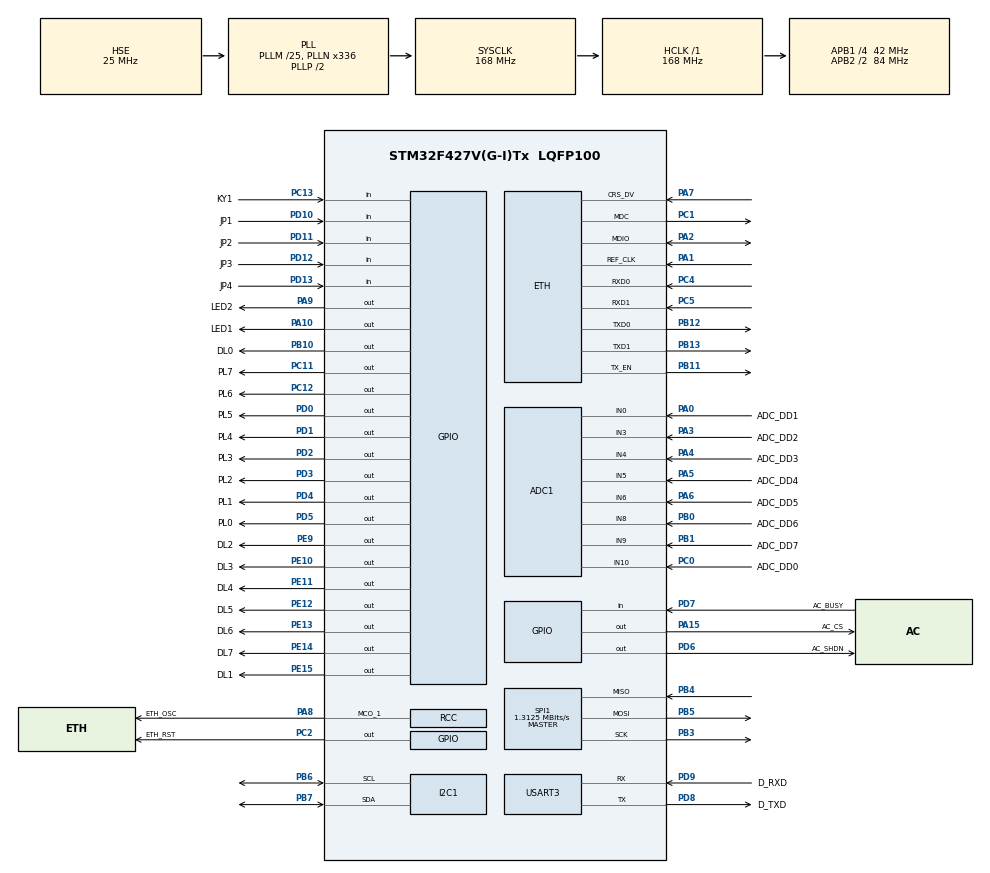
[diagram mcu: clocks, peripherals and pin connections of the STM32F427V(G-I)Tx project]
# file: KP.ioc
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ADC1.Channel-0\#ChannelRegularConversion=ADC_CHANNEL_10
ADC1.Channel-1\#ChannelRegularConversion=ADC_CHANNEL_0
ADC1.Channel-2\#ChannelRegularConversion=ADC_CHANNEL_3
ADC1.Channel-3\#ChannelRegularConversion=ADC_CHANNEL_4
ADC1.Channel-4\#ChannelRegularConversion=ADC_CHANNEL_5
ADC1.Channel-5\#ChannelRegularConversion=ADC_CHANNEL_6
ADC1.Channel-6\#ChannelRegularConversion=ADC_CHANNEL_8
ADC1.Channel-7\#ChannelRegularConversion=ADC_CHANNEL_9
ADC1.ContinuousConvMode=ENABLE
ADC1.DMAContinuousRequests=ENABLE
ADC1.ExternalTrigConv=ADC_SOFTWARE_START
ADC1.NbrOfConversion=8
ADC1.NbrOfConversionFlag=1
ADC1.Rank-0\#ChannelRegularConversion=1
ADC1.Rank-1\#ChannelRegularConversion=2
ADC1.Rank-2\#ChannelRegularConversion=3
ADC1.Rank-3\#ChannelRegularConversion=4
ADC1.Rank-4\#ChannelRegularConversion=5
ADC1.Rank-5\#ChannelRegularConversion=6
ADC1.Rank-6\#ChannelRegularConversion=7
ADC1.Rank-7\#ChannelRegularConversion=8
ADC1.SamplingTime-0\#ChannelRegularConversion=ADC_SAMPLETIME_15CYCLES
ADC1.SamplingTime-1\#ChannelRegularConversion=ADC_SAMPLETIME_15CYCLES
ADC1.SamplingTime-2\#ChannelRegularConversion=ADC_SAMPLETIME_15CYCLES
ADC1.SamplingTime-3\#ChannelRegularConversion=ADC_SAMPLETIME_15CYCLES
ADC1.SamplingTime-4\#ChannelRegularConversion=ADC_SAMPLETIME_15CYCLES
ADC1.SamplingTime-5\#ChannelRegularConversion=ADC_SAMPLETIME_15CYCLES
ADC1.SamplingTime-6\#ChannelRegularConversion=ADC_SAMPLETIME_15CYCLES
ADC1.SamplingTime-7\#ChannelRegularConversion=ADC_SAMPLETIME_15CYCLES
ADC1.ScanConvMode=ENABLE
ADC1.master=1
Dma.ADC1.0.Direction=DMA_PERIPH_TO_MEMORY
Dma.ADC1.0.FIFOMode=DMA_FIFOMODE_DISABLE
Dma.ADC1.0.Instance=DMA2_Stream0
Dma.ADC1.0.MemDataAlignment=DMA_MDATAALIGN_HALFWORD
Dma.ADC1.0.MemInc=DMA_MINC_ENABLE
Dma.ADC1.0.Mode=DMA_NORMAL
Dma.ADC1.0.PeriphDataAlignment=DMA_PDATAALIGN_HALFWORD
Dma.ADC1.0.PeriphInc=DMA_PINC_DISABLE
Dma.ADC1.0.Priority=DMA_PRIORITY_LOW
Dma.Request0=ADC1
Dma.Request1=SPI1_RX
Dma.Request2=SPI1_TX
Dma.SPI1_RX.1.Direction=DMA_PERIPH_TO_MEMORY
Dma.SPI1_RX.1.FIFOMode=DMA_FIFOMODE_DISABLE
Dma.SPI1_RX.1.Instance=DMA2_Stream2
Dma.SPI1_RX.1.MemDataAlignment=DMA_MDATAALIGN_BYTE
Dma.SPI1_RX.1.MemInc=DMA_MINC_ENABLE
Dma.SPI1_RX.1.Mode=DMA_NORMAL
Dma.SPI1_RX.1.PeriphDataAlignment=DMA_PDATAALIGN_BYTE
Dma.SPI1_RX.1.PeriphInc=DMA_PINC_DISABLE
Dma.SPI1_RX.1.Priority=DMA_PRIORITY_LOW
Dma.SPI1_TX.2.Direction=DMA_MEMORY_TO_PERIPH
Dma.SPI1_TX.2.FIFOMode=DMA_FIFOMODE_DISABLE
Dma.SPI1_TX.2.Instance=DMA2_Stream3
Dma.SPI1_TX.2.MemDataAlignment=DMA_MDATAALIGN_BYTE
Dma.SPI1_TX.2.MemInc=DMA_MINC_ENABLE
Dma.SPI1_TX.2.Mode=DMA_NORMAL
Dma.SPI1_TX.2.PeriphDataAlignment=DMA_PDATAALIGN_BYTE
Dma.SPI1_TX.2.PeriphInc=DMA_PINC_DISABLE
Dma.SPI1_TX.2.Priority=DMA_PRIORITY_LOW
ETH.MACAddr=00\:80\:E1\:00\:12\:35
ETH.MediaInterface=ETH_MEDIA_INTERFACE_RMII
ETH.PhyAddress=0
FREERTOS.Mutexes01=mutex_OutText,Static,mutex_OutTextControlBlock
FREERTOS.Tasks01=defaultTask,0,512,StartDefaultTask,Default,NULL,Dynamic,NULL,NULL
FREERTOS.configGENERATE_RUN_TIME_STATS=0
FREERTOS.configMINIMAL_STACK_SIZE=128
FREERTOS.configTOTAL_HEAP_SIZE=49152
FREERTOS.configUSE_NEWLIB_REENTRANT=1
FREERTOS.configUSE_STATS_FORMATTING_FUNCTIONS=1
FREERTOS.configUSE_TIMERS=1
FREERTOS.configUSE_TRACE_FACILITY=1
LWIP.DEFAULT_RAW_RECVMBOX_SIZE=6
LWIP.GATEWAY_ADDRESS=192.168.254.254
LWIP.IP_ADDRESS=192.168.254.191
LWIP.LWIP_DHCP=1
LWIP.LWIP_DNS=1
LWIP.LWIP_NETIF_STATUS_CALLBACK=1
LWIP.LWIP_RAW=1
LWIP.LWIP_SO_RCVTIMEO=1
LWIP.MEMP_NUM_TCP_PCB=5
LWIP.MEM_SIZE=24576
LWIP.NETMASK_ADDRESS=255.255.255.000
LWIP.Version=v2.1.2_Cube
Mcu.Family=STM32F4
Mcu.Name=STM32F427V(G-I)Tx
Mcu.Package=LQFP100
NVIC.DMA2_Stream0_IRQn=true\:8\:0\:true\:false\:true\:true\:false\:true
NVIC.DMA2_Stream2_IRQn=true\:6\:0\:true\:false\:true\:true\:false\:true
NVIC.DMA2_Stream3_IRQn=true\:6\:0\:true\:false\:true\:true\:false\:true
NVIC.ETH_IRQn=true\:7\:0\:true\:false\:true\:false\:false\:true
NVIC.PriorityGroup=NVIC_PRIORITYGROUP_4
NVIC.TIM1_UP_TIM10_IRQn=true\:0\:0\:false\:false\:true\:false\:false\:true
NVIC.TIM2_IRQn=true\:0\:0\:false\:false\:true\:true\:true\:true
NVIC.TimeBase=TIM1_UP_TIM10_IRQn
NVIC.TimeBaseIP=TIM1
PA0/WKUP.GPIO_Label=ADC_DD1
PA0/WKUP.Signal=ADCx_IN0
PA1.Mode=RMII
PA1.Signal=ETH_REF_CLK
PA10.GPIO_Label=LED1
PA10.PinState=GPIO_PIN_SET
PA10.Signal=GPIO_Output
PA13.Mode=Serial_Wire
PA13.Signal=SYS_JTMS-SWDIO
PA14.Mode=Serial_Wire
PA14.Signal=SYS_JTCK-SWCLK
PA15.GPIO_Label=AC_CS
PA15.GPIO_Speed=GPIO_SPEED_FREQ_HIGH
PA15.PinState=GPIO_PIN_SET
PA15.Signal=GPIO_Output
PA2.GPIO_PuPd=GPIO_PULLUP
PA2.Mode=RMII
PA2.Signal=ETH_MDIO
PA3.GPIO_Label=ADC_DD2
PA3.Signal=ADCx_IN3
PA4.GPIO_Label=ADC_DD3
PA4.Signal=ADCx_IN4
PA5.GPIO_Label=ADC_DD4
PA5.Signal=ADCx_IN5
PA6.GPIO_Label=ADC_DD5
PA6.Signal=ADCx_IN6
PA7.Mode=RMII
PA7.Signal=ETH_CRS_DV
PA8.GPIO_Label=ETH_OSC
PA8.Mode=Clock-out-1
PA8.Signal=RCC_MCO_1
PA9.GPIO_Label=LED2
PA9.PinState=GPIO_PIN_SET
PA9.Signal=GPIO_Output
PB0.GPIO_Label=ADC_DD6
PB0.Signal=ADCx_IN8
PB1.GPIO_Label=ADC_DD7
PB1.Signal=ADCx_IN9
PB10.GPIO_Label=DL0
PB10.Signal=GPIO_Output
PB11.Mode=RMII
PB11.Signal=ETH_TX_EN
PB12.Mode=RMII
PB12.Signal=ETH_TXD0
PB13.Mode=RMII
PB13.Signal=ETH_TXD1
PB3.Mode=Full_Duplex_Master
PB3.Signal=SPI1_SCK
PB4.Mode=Full_Duplex_Master
PB4.Signal=SPI1_MISO
PB5.Mode=Full_Duplex_Master
PB5.Signal=SPI1_MOSI
PB6.Mode=I2C
PB6.Signal=I2C1_SCL
PB7.Mode=I2C
PB7.Signal=I2C1_SDA
PC0.GPIO_Label=ADC_DD0
PC0.Signal=ADCx_IN10
PC1.Mode=RMII
PC1.Signal=ETH_MDC
PC11.GPIO_Label=PL7
PC11.Signal=GPIO_Output
PC12.GPIO_Label=PL6
PC12.Signal=GPIO_Output
PC13.GPIO_Label=KY1
PC13.Signal=GPIO_Input
PC2.GPIO_Label=ETH_RST
PC2.Signal=GPIO_Output
PC4.Mode=RMII
PC4.Signal=ETH_RXD0
PC5.Mode=RMII
PC5.Signal=ETH_RXD1
PD0.GPIO_Label=PL5
PD0.Signal=GPIO_Output
PD1.GPIO_Label=PL4
PD1.Signal=GPIO_Output
PD10.GPIO_Label=JP1
PD10.GPIO_PuPd=GPIO_PULLUP
PD10.Signal=GPIO_Input
PD11.GPIO_Label=JP2
PD11.GPIO_PuPd=GPIO_PULLUP
PD11.Signal=GPIO_Input
PD12.GPIO_Label=JP3
PD12.GPIO_PuPd=GPIO_PULLUP
PD12.Signal=GPIO_Input
PD13.GPIO_Label=JP4
PD13.GPIO_PuPd=GPIO_PULLUP
PD13.Signal=GPIO_Input
PD2.GPIO_Label=PL3
PD2.Signal=GPIO_Output
PD3.GPIO_Label=PL2
PD3.Signal=GPIO_Output
PD4.GPIO_Label=PL1
PD4.Signal=GPIO_Output
PD5.GPIO_Label=PL0
PD5.Signal=GPIO_Output
PD6.GPIO_Label=AC_SHDN
PD6.PinState=GPIO_PIN_SET
PD6.Signal=GPIO_Output
PD7.GPIO_Label=AC_BUSY
PD7.Signal=GPIO_Input
PD8.GPIO_Label=D_TXD
PD8.Mode=Asynchronous
PD8.Signal=USART3_TX
PD9.GPIO_Label=D_RXD
PD9.Mode=Asynchronous
PD9.Signal=USART3_RX
PE10.GPIO_Label=DL3
PE10.Signal=GPIO_Output
PE11.GPIO_Label=DL4
PE11.Signal=GPIO_Output
PE12.GPIO_Label=DL5
PE12.Signal=GPIO_Output
PE13.GPIO_Label=DL6
PE13.Signal=GPIO_Output
PE14.GPIO_Label=DL7
PE14.Signal=GPIO_Output
PE15.GPIO_Label=DL1
PE15.Signal=GPIO_Output
PE9.GPIO_Label=DL2
PE9.Signal=GPIO_Output
PH0/OSC_IN.Mode=HSE-External-Oscillator
PH0/OSC_IN.Signal=RCC_OSC_IN
PH1/OSC_OUT.Mode=HSE-External-Oscillator
PH1/OSC_OUT.Signal=RCC_OSC_OUT
ProjectManager.HeapSize=0x2000
ProjectManager.StackSize=0x4000
ProjectManager.TargetToolchain=STM32CubeIDE
RCC.48MHZClocksFreq_Value=48000000
RCC.AHBFreq_Value=168000000
RCC.APB1CLKDivider=RCC_HCLK_DIV4
RCC.APB1Freq_Value=42000000
RCC.APB1TimFreq_Value=84000000
RCC.APB2CLKDivider=RCC_HCLK_DIV2
RCC.APB2Freq_Value=84000000
RCC.APB2TimFreq_Value=168000000
RCC.CortexFreq_Value=168000000
RCC.HCLKFreq_Value=168000000
RCC.HSE_VALUE=25000000
RCC.HSI_VALUE=16000000
RCC.LSE_VALUE=32768
RCC.PLLM=25
RCC.PLLN=336
RCC.PLLQ=7
RCC.PLLSourceVirtual=RCC_PLLSOURCE_HSE
RCC.RCC_MCO1Source=RCC_MCO1SOURCE_HSE
RCC.SYSCLKFreq_VALUE=168000000
RCC.SYSCLKSource=RCC_SYSCLKSOURCE_PLLCLK
RCC.VCOOutputFreq_Value=336000000
SH.ADCx_IN0.0=ADC1_IN0,IN0
SH.ADCx_IN10.0=ADC1_IN10,IN10
SH.ADCx_IN3.0=ADC1_IN3,IN3
SH.ADCx_IN4.0=ADC1_IN4,IN4
SH.ADCx_IN5.0=ADC1_IN5,IN5
SH.ADCx_IN6.0=ADC1_IN6,IN6
SH.ADCx_IN8.0=ADC1_IN8,IN8
SH.ADCx_IN9.0=ADC1_IN9,IN9
SPI1.BaudRatePrescaler=SPI_BAUDRATEPRESCALER_64
SPI1.CalculateBaudRate=1.3125 MBits/s
SPI1.Direction=SPI_DIRECTION_2LINES
SPI1.Mode=SPI_MODE_MASTER
SPI1.VirtualType=VM_MASTER
TIM2.AutoReloadPreload=TIM_AUTORELOAD_PRELOAD_ENABLE
TIM2.Period=499
TIM2.Prescaler=83
USART3.VirtualMode=VM_ASYNC
VP_FREERTOS_VS_CMSIS_V1.Mode=CMSIS_V1
VP_LWIP_VS_Enabled.Mode=Enabled
VP_RNG_VS_RNG.Mode=RNG_Activate
VP_SYS_VS_tim1.Mode=TIM1
VP_TIM2_VS_ClockSourceINT.Mode=Internal
board=custom

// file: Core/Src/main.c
/* USER CODE BEGIN Header */
/**
  ******************************************************************************
  * @file           : main.c
  * @brief          : Main program body
  ******************************************************************************
  * @attention
  *
  * <h2><center>&copy; Copyright (c) 2020 STMicroelectronics.
  * All rights reserved.</center></h2>
  *
  * This software component is licensed by ST under Ultimate Liberty license
  * SLA0044, the "License"; You may not use this file except in compliance with
  * the License. You may obtain a copy of the License at:
  *                             www.st.com/SLA0044
  *
  ******************************************************************************
  */
/* USER CODE END Header */
#include "main.h"
#include "cmsis_os.h"
#include "lwip.h"

ADC_HandleTypeDef hadc1;
DMA_HandleTypeDef hdma_adc1;

I2C_HandleTypeDef hi2c1;

RNG_HandleTypeDef hrng;

SPI_HandleTypeDef hspi1;
DMA_HandleTypeDef hdma_spi1_rx;
DMA_HandleTypeDef hdma_spi1_tx;

TIM_HandleTypeDef htim2;

UART_HandleTypeDef huart3;

osThreadId defaultTaskHandle;
osMutexId mutex_OutTextHandle;
osStaticMutexDef_t mutex_OutTextControlBlock;
/* USER CODE BEGIN PV */
extern void  uMainCont(void);
extern void  Tim2CallBack(void);

/* USER CODE END PV */

void SystemClock_Config(void);
static void MX_GPIO_Init(void);
static void MX_DMA_Init(void);
static void MX_ADC1_Init(void);
static void MX_USART3_UART_Init(void);
static void MX_SPI1_Init(void);
static void MX_I2C1_Init(void);
static void MX_TIM2_Init(void);
static void MX_RNG_Init(void);
void StartDefaultTask(void const * argument);

/* USER CODE BEGIN 0 */
void callResCubeMX() {
	  MX_GPIO_Init();
	  MX_DMA_Init();
	  MX_ADC1_Init();
	  //MX_USART3_UART_Init();
	  MX_SPI1_Init();
	  //MX_I2C1_Init();
	  MX_TIM2_Init();

}
/* USER CODE END 0 */

int main(void)
{

  /* MCU Configuration--------------------------------------------------------*/

  /* Reset of all peripherals, Initializes the Flash interface and the Systick. */
  HAL_Init();

  /* Configure the system clock */
  SystemClock_Config();

  /* USER CODE BEGIN SysInit */

  //------------------------------------------------------------------------------
  // przeskok do uMain
  //------------------------------------------------------------------------------

  uMainCont();

  /* USER CODE END SysInit */

  /* Initialize all configured peripherals */
  MX_GPIO_Init();
  MX_DMA_Init();
  MX_ADC1_Init();
  MX_USART3_UART_Init();
  MX_SPI1_Init();
  MX_I2C1_Init();
  MX_TIM2_Init();
  MX_RNG_Init();

  /* Create the mutex(es) */
  /* definition and creation of mutex_OutText */
  osMutexStaticDef(mutex_OutText, &mutex_OutTextControlBlock);
  mutex_OutTextHandle = osMutexCreate(osMutex(mutex_OutText));

  /* Create the thread(s) */
  /* definition and creation of defaultTask */
  osThreadDef(defaultTask, StartDefaultTask, osPriorityNormal, 0, 512);
  defaultTaskHandle = osThreadCreate(osThread(defaultTask), NULL);

  /* Start scheduler */
  osKernelStart();

  /* We should never get here as control is now taken by the scheduler */
  /* Infinite loop */
  while (1)
  {

  }
}

void SystemClock_Config(void)
{
  RCC_OscInitTypeDef RCC_OscInitStruct = {0};
  RCC_ClkInitTypeDef RCC_ClkInitStruct = {0};

  /** Configure the main internal regulator output voltage
  */
  __HAL_RCC_PWR_CLK_ENABLE();
  __HAL_PWR_VOLTAGESCALING_CONFIG(PWR_REGULATOR_VOLTAGE_SCALE1);
  /** Initializes the RCC Oscillators according to the specified parameters
  * in the RCC_OscInitTypeDef structure.
  */
  RCC_OscInitStruct.OscillatorType = RCC_OSCILLATORTYPE_HSE;
  RCC_OscInitStruct.HSEState = RCC_HSE_ON;
  RCC_OscInitStruct.PLL.PLLState = RCC_PLL_ON;
  RCC_OscInitStruct.PLL.PLLSource = RCC_PLLSOURCE_HSE;
  RCC_OscInitStruct.PLL.PLLM = 25;
  RCC_OscInitStruct.PLL.PLLN = 336;
  RCC_OscInitStruct.PLL.PLLP = RCC_PLLP_DIV2;
  RCC_OscInitStruct.PLL.PLLQ = 7;
  if (HAL_RCC_OscConfig(&RCC_OscInitStruct) != HAL_OK)
  {
    Error_Handler();
  }
  /** Initializes the CPU, AHB and APB buses clocks
  */
  RCC_ClkInitStruct.ClockType = RCC_CLOCKTYPE_HCLK|RCC_CLOCKTYPE_SYSCLK
                              |RCC_CLOCKTYPE_PCLK1|RCC_CLOCKTYPE_PCLK2;
  RCC_ClkInitStruct.SYSCLKSource = RCC_SYSCLKSOURCE_PLLCLK;
  RCC_ClkInitStruct.AHBCLKDivider = RCC_SYSCLK_DIV1;
  RCC_ClkInitStruct.APB1CLKDivider = RCC_HCLK_DIV4;
  RCC_ClkInitStruct.APB2CLKDivider = RCC_HCLK_DIV2;

  if (HAL_RCC_ClockConfig(&RCC_ClkInitStruct, FLASH_LATENCY_5) != HAL_OK)
  {
    Error_Handler();
  }
  HAL_RCC_MCOConfig(RCC_MCO1, RCC_MCO1SOURCE_HSE, RCC_MCODIV_1);
}

static void MX_ADC1_Init(void)
{

  ADC_ChannelConfTypeDef sConfig = {0};

  /** Configure the global features of the ADC (Clock, Resolution, Data Alignment and number of conversion)
  */
  hadc1.Instance = ADC1;
  hadc1.Init.ClockPrescaler = ADC_CLOCK_SYNC_PCLK_DIV4;
  hadc1.Init.Resolution = ADC_RESOLUTION_12B;
  hadc1.Init.ScanConvMode = ENABLE;
  hadc1.Init.ContinuousConvMode = ENABLE;
  hadc1.Init.DiscontinuousConvMode = DISABLE;
  hadc1.Init.ExternalTrigConvEdge = ADC_EXTERNALTRIGCONVEDGE_NONE;
  hadc1.Init.ExternalTrigConv = ADC_SOFTWARE_START;
  hadc1.Init.DataAlign = ADC_DATAALIGN_RIGHT;
  hadc1.Init.NbrOfConversion = 8;
  hadc1.Init.DMAContinuousRequests = ENABLE;
  hadc1.Init.EOCSelection = ADC_EOC_SINGLE_CONV;
  if (HAL_ADC_Init(&hadc1) != HAL_OK)
  {
    Error_Handler();
  }
  /** Configure for the selected ADC regular channel its corresponding rank in the sequencer and its sample time.
  */
  sConfig.Channel = ADC_CHANNEL_10;
  sConfig.Rank = 1;
  sConfig.SamplingTime = ADC_SAMPLETIME_15CYCLES;
  if (HAL_ADC_ConfigChannel(&hadc1, &sConfig) != HAL_OK)
  {
    Error_Handler();
  }
  /** Configure for the selected ADC regular channel its corresponding rank in the sequencer and its sample time.
  */
  sConfig.Channel = ADC_CHANNEL_0;
  sConfig.Rank = 2;
  if (HAL_ADC_ConfigChannel(&hadc1, &sConfig) != HAL_OK)
  {
    Error_Handler();
  }
  /** Configure for the selected ADC regular channel its corresponding rank in the sequencer and its sample time.
  */
  sConfig.Channel = ADC_CHANNEL_3;
  sConfig.Rank = 3;
  if (HAL_ADC_ConfigChannel(&hadc1, &sConfig) != HAL_OK)
  {
    Error_Handler();
  }
  /** Configure for the selected ADC regular channel its corresponding rank in the sequencer and its sample time.
  */
  sConfig.Channel = ADC_CHANNEL_4;
  sConfig.Rank = 4;
  if (HAL_ADC_ConfigChannel(&hadc1, &sConfig) != HAL_OK)
  {
    Error_Handler();
  }
  /** Configure for the selected ADC regular channel its corresponding rank in the sequencer and its sample time.
  */
  sConfig.Channel = ADC_CHANNEL_5;
  sConfig.Rank = 5;
  if (HAL_ADC_ConfigChannel(&hadc1, &sConfig) != HAL_OK)
  {
    Error_Handler();
  }
  /** Configure for the selected ADC regular channel its corresponding rank in the sequencer and its sample time.
  */
  sConfig.Channel = ADC_CHANNEL_6;
  sConfig.Rank = 6;
  if (HAL_ADC_ConfigChannel(&hadc1, &sConfig) != HAL_OK)
  {
    Error_Handler();
  }
  /** Configure for the selected ADC regular channel its corresponding rank in the sequencer and its sample time.
  */
  sConfig.Channel = ADC_CHANNEL_8;
  sConfig.Rank = 7;
  if (HAL_ADC_ConfigChannel(&hadc1, &sConfig) != HAL_OK)
  {
    Error_Handler();
  }
  /** Configure for the selected ADC regular channel its corresponding rank in the sequencer and its sample time.
  */
  sConfig.Channel = ADC_CHANNEL_9;
  sConfig.Rank = 8;
  if (HAL_ADC_ConfigChannel(&hadc1, &sConfig) != HAL_OK)
  {
    Error_Handler();
  }

}

static void MX_I2C1_Init(void)
{

  hi2c1.Instance = I2C1;
  hi2c1.Init.ClockSpeed = 100000;
  hi2c1.Init.DutyCycle = I2C_DUTYCYCLE_2;
  hi2c1.Init.OwnAddress1 = 0;
  hi2c1.Init.AddressingMode = I2C_ADDRESSINGMODE_7BIT;
  hi2c1.Init.DualAddressMode = I2C_DUALADDRESS_DISABLE;
  hi2c1.Init.OwnAddress2 = 0;
  hi2c1.Init.GeneralCallMode = I2C_GENERALCALL_DISABLE;
  hi2c1.Init.NoStretchMode = I2C_NOSTRETCH_DISABLE;
  if (HAL_I2C_Init(&hi2c1) != HAL_OK)
  {
    Error_Handler();
  }
  /** Configure Analogue filter
  */
  if (HAL_I2CEx_ConfigAnalogFilter(&hi2c1, I2C_ANALOGFILTER_ENABLE) != HAL_OK)
  {
    Error_Handler();
  }
  /** Configure Digital filter
  */
  if (HAL_I2CEx_ConfigDigitalFilter(&hi2c1, 0) != HAL_OK)
  {
    Error_Handler();
  }

}

static void MX_RNG_Init(void)
{

  hrng.Instance = RNG;
  if (HAL_RNG_Init(&hrng) != HAL_OK)
  {
    Error_Handler();
  }

}

static void MX_SPI1_Init(void)
{

  /* SPI1 parameter configuration*/
  hspi1.Instance = SPI1;
  hspi1.Init.Mode = SPI_MODE_MASTER;
  hspi1.Init.Direction = SPI_DIRECTION_2LINES;
  hspi1.Init.DataSize = SPI_DATASIZE_8BIT;
  hspi1.Init.CLKPolarity = SPI_POLARITY_LOW;
  hspi1.Init.CLKPhase = SPI_PHASE_1EDGE;
  hspi1.Init.NSS = SPI_NSS_SOFT;
  hspi1.Init.BaudRatePrescaler = SPI_BAUDRATEPRESCALER_64;
  hspi1.Init.FirstBit = SPI_FIRSTBIT_MSB;
  hspi1.Init.TIMode = SPI_TIMODE_DISABLE;
  hspi1.Init.CRCCalculation = SPI_CRCCALCULATION_DISABLE;
  hspi1.Init.CRCPolynomial = 10;
  if (HAL_SPI_Init(&hspi1) != HAL_OK)
  {
    Error_Handler();
  }

}

static void MX_TIM2_Init(void)
{

  TIM_ClockConfigTypeDef sClockSourceConfig = {0};
  TIM_MasterConfigTypeDef sMasterConfig = {0};

  htim2.Instance = TIM2;
  htim2.Init.Prescaler = 83;
  htim2.Init.CounterMode = TIM_COUNTERMODE_UP;
  htim2.Init.Period = 499;
  htim2.Init.ClockDivision = TIM_CLOCKDIVISION_DIV1;
  htim2.Init.AutoReloadPreload = TIM_AUTORELOAD_PRELOAD_ENABLE;
  if (HAL_TIM_Base_Init(&htim2) != HAL_OK)
  {
    Error_Handler();
  }
  sClockSourceConfig.ClockSource = TIM_CLOCKSOURCE_INTERNAL;
  if (HAL_TIM_ConfigClockSource(&htim2, &sClockSourceConfig) != HAL_OK)
  {
    Error_Handler();
  }
  sMasterConfig.MasterOutputTrigger = TIM_TRGO_RESET;
  sMasterConfig.MasterSlaveMode = TIM_MASTERSLAVEMODE_DISABLE;
  if (HAL_TIMEx_MasterConfigSynchronization(&htim2, &sMasterConfig) != HAL_OK)
  {
    Error_Handler();
  }

}

static void MX_USART3_UART_Init(void)
{

  huart3.Instance = USART3;
  huart3.Init.BaudRate = 115200;
  huart3.Init.WordLength = UART_WORDLENGTH_8B;
  huart3.Init.StopBits = UART_STOPBITS_1;
  huart3.Init.Parity = UART_PARITY_NONE;
  huart3.Init.Mode = UART_MODE_TX_RX;
  huart3.Init.HwFlowCtl = UART_HWCONTROL_NONE;
  huart3.Init.OverSampling = UART_OVERSAMPLING_16;
  if (HAL_UART_Init(&huart3) != HAL_OK)
  {
    Error_Handler();
  }

}

static void MX_DMA_Init(void)
{

  /* DMA controller clock enable */
  __HAL_RCC_DMA2_CLK_ENABLE();

  /* DMA interrupt init */
  /* DMA2_Stream0_IRQn interrupt configuration */
  HAL_NVIC_SetPriority(DMA2_Stream0_IRQn, 8, 0);
  HAL_NVIC_EnableIRQ(DMA2_Stream0_IRQn);
  /* DMA2_Stream2_IRQn interrupt configuration */
  HAL_NVIC_SetPriority(DMA2_Stream2_IRQn, 6, 0);
  HAL_NVIC_EnableIRQ(DMA2_Stream2_IRQn);
  /* DMA2_Stream3_IRQn interrupt configuration */
  HAL_NVIC_SetPriority(DMA2_Stream3_IRQn, 6, 0);
  HAL_NVIC_EnableIRQ(DMA2_Stream3_IRQn);

}

static void MX_GPIO_Init(void)
{
  GPIO_InitTypeDef GPIO_InitStruct = {0};

  /* GPIO Ports Clock Enable */
  __HAL_RCC_GPIOC_CLK_ENABLE();
  __HAL_RCC_GPIOH_CLK_ENABLE();
  __HAL_RCC_GPIOA_CLK_ENABLE();
  __HAL_RCC_GPIOB_CLK_ENABLE();
  __HAL_RCC_GPIOE_CLK_ENABLE();
  __HAL_RCC_GPIOD_CLK_ENABLE();

  /*Configure GPIO pin Output Level */
  HAL_GPIO_WritePin(GPIOC, ETH_RST_Pin|PL7_Pin|PL6_Pin, GPIO_PIN_RESET);

  /*Configure GPIO pin Output Level */
  HAL_GPIO_WritePin(GPIOE, DL2_Pin|DL3_Pin|DL4_Pin|DL5_Pin
                          |DL6_Pin|DL7_Pin|DL1_Pin, GPIO_PIN_RESET);

  /*Configure GPIO pin Output Level */
  HAL_GPIO_WritePin(DL0_GPIO_Port, DL0_Pin, GPIO_PIN_RESET);

  /*Configure GPIO pin Output Level */
  HAL_GPIO_WritePin(GPIOA, LED2_Pin|LED1_Pin|AC_CS_Pin, GPIO_PIN_SET);

  /*Configure GPIO pin Output Level */
  HAL_GPIO_WritePin(GPIOD, PL5_Pin|PL4_Pin|PL3_Pin|PL2_Pin
                          |PL1_Pin|PL0_Pin, GPIO_PIN_RESET);

  /*Configure GPIO pin Output Level */
  HAL_GPIO_WritePin(AC_SHDN_GPIO_Port, AC_SHDN_Pin, GPIO_PIN_SET);

  /*Configure GPIO pin : KY1_Pin */
  GPIO_InitStruct.Pin = KY1_Pin;
  GPIO_InitStruct.Mode = GPIO_MODE_INPUT;
  GPIO_InitStruct.Pull = GPIO_NOPULL;
  HAL_GPIO_Init(KY1_GPIO_Port, &GPIO_InitStruct);

  /*Configure GPIO pins : ETH_RST_Pin PL7_Pin PL6_Pin */
  GPIO_InitStruct.Pin = ETH_RST_Pin|PL7_Pin|PL6_Pin;
  GPIO_InitStruct.Mode = GPIO_MODE_OUTPUT_PP;
  GPIO_InitStruct.Pull = GPIO_NOPULL;
  GPIO_InitStruct.Speed = GPIO_SPEED_FREQ_LOW;
  HAL_GPIO_Init(GPIOC, &GPIO_InitStruct);

  /*Configure GPIO pins : DL2_Pin DL3_Pin DL4_Pin DL5_Pin
                           DL6_Pin DL7_Pin DL1_Pin */
  GPIO_InitStruct.Pin = DL2_Pin|DL3_Pin|DL4_Pin|DL5_Pin
                          |DL6_Pin|DL7_Pin|DL1_Pin;
  GPIO_InitStruct.Mode = GPIO_MODE_OUTPUT_PP;
  GPIO_InitStruct.Pull = GPIO_NOPULL;
  GPIO_InitStruct.Speed = GPIO_SPEED_FREQ_LOW;
  HAL_GPIO_Init(GPIOE, &GPIO_InitStruct);

  /*Configure GPIO pin : DL0_Pin */
  GPIO_InitStruct.Pin = DL0_Pin;
  GPIO_InitStruct.Mode = GPIO_MODE_OUTPUT_PP;
  GPIO_InitStruct.Pull = GPIO_NOPULL;
  GPIO_InitStruct.Speed = GPIO_SPEED_FREQ_LOW;
  HAL_GPIO_Init(DL0_GPIO_Port, &GPIO_InitStruct);

  /*Configure GPIO pins : JP1_Pin JP2_Pin JP3_Pin JP4_Pin */
  GPIO_InitStruct.Pin = JP1_Pin|JP2_Pin|JP3_Pin|JP4_Pin;
  GPIO_InitStruct.Mode = GPIO_MODE_INPUT;
  GPIO_InitStruct.Pull = GPIO_PULLUP;
  HAL_GPIO_Init(GPIOD, &GPIO_InitStruct);

  /*Configure GPIO pin : ETH_OSC_Pin */
  GPIO_InitStruct.Pin = ETH_OSC_Pin;
  GPIO_InitStruct.Mode = GPIO_MODE_AF_PP;
  GPIO_InitStruct.Pull = GPIO_NOPULL;
  GPIO_InitStruct.Speed = GPIO_SPEED_FREQ_LOW;
  GPIO_InitStruct.Alternate = GPIO_AF0_MCO;
  HAL_GPIO_Init(ETH_OSC_GPIO_Port, &GPIO_InitStruct);

  /*Configure GPIO pins : LED2_Pin LED1_Pin */
  GPIO_InitStruct.Pin = LED2_Pin|LED1_Pin;
  GPIO_InitStruct.Mode = GPIO_MODE_OUTPUT_PP;
  GPIO_InitStruct.Pull = GPIO_NOPULL;
  GPIO_InitStruct.Speed = GPIO_SPEED_FREQ_LOW;
  HAL_GPIO_Init(GPIOA, &GPIO_InitStruct);

  /*Configure GPIO pin : AC_CS_Pin */
  GPIO_InitStruct.Pin = AC_CS_Pin;
  GPIO_InitStruct.Mode = GPIO_MODE_OUTPUT_PP;
  GPIO_InitStruct.Pull = GPIO_NOPULL;
  GPIO_InitStruct.Speed = GPIO_SPEED_FREQ_HIGH;
  HAL_GPIO_Init(AC_CS_GPIO_Port, &GPIO_InitStruct);

  /*Configure GPIO pins : PL5_Pin PL4_Pin PL3_Pin PL2_Pin
                           PL1_Pin PL0_Pin AC_SHDN_Pin */
  GPIO_InitStruct.Pin = PL5_Pin|PL4_Pin|PL3_Pin|PL2_Pin
                          |PL1_Pin|PL0_Pin|AC_SHDN_Pin;
  GPIO_InitStruct.Mode = GPIO_MODE_OUTPUT_PP;
  GPIO_InitStruct.Pull = GPIO_NOPULL;
  GPIO_InitStruct.Speed = GPIO_SPEED_FREQ_LOW;
  HAL_GPIO_Init(GPIOD, &GPIO_InitStruct);

  /*Configure GPIO pin : AC_BUSY_Pin */
  GPIO_InitStruct.Pin = AC_BUSY_Pin;
  GPIO_InitStruct.Mode = GPIO_MODE_INPUT;
  GPIO_InitStruct.Pull = GPIO_NOPULL;
  HAL_GPIO_Init(AC_BUSY_GPIO_Port, &GPIO_InitStruct);

}

void StartDefaultTask(void const * argument)
{
  /* init code for LWIP */
  MX_LWIP_Init();
  for(;;)
  {
  }
}

void HAL_TIM_PeriodElapsedCallback(TIM_HandleTypeDef *htim)
{
  if (htim->Instance == TIM1) {
    HAL_IncTick();
  }
  /* USER CODE BEGIN Callback 1 */
  else if (htim->Instance == TIM2){
	Tim2CallBack();
  }
  /* USER CODE END Callback 1 */
}

void Error_Handler(void)
{
}

/************************ (C) COPYRIGHT STMicroelectronics *****END OF FILE****/
